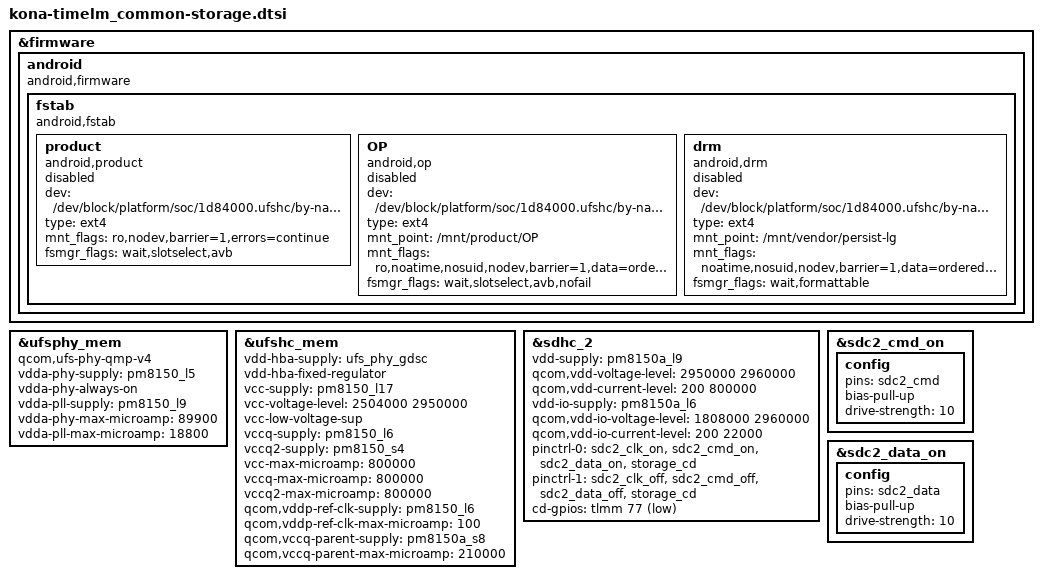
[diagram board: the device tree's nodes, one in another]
// SPDX-License-Identifier: GPL-2.0-only
/*
 * Copyright (c) 2018-2019, The Linux Foundation. All rights reserved.
 */

&firmware {
	android {
		compatible = "android,firmware";
		fstab {
			compatible = "android,fstab";
			product {
				compatible = "android,product";
				dev = "/dev/block/platform/soc/1d84000.ufshc/by-name/product";
				type = "ext4";
				mnt_flags = "ro,nodev,barrier=1,errors=continue";
				fsmgr_flags = "wait,slotselect,avb";
				status = "disabled";
			};
			OP {
				compatible = "android,op";
				dev = "/dev/block/platform/soc/1d84000.ufshc/by-name/OP";
				type = "ext4";
				mnt_point = "/mnt/product/OP";
				mnt_flags = "ro,noatime,nosuid,nodev,barrier=1,data=ordered,noauto_da_alloc";
				fsmgr_flags = "wait,slotselect,avb,nofail";
				status = "disabled";
			};
			drm {
				compatible = "android,drm";
				dev = "/dev/block/platform/soc/1d84000.ufshc/by-name/drm";
				type = "ext4";
				mnt_point = "/mnt/vendor/persist-lg";
				mnt_flags = "noatime,nosuid,nodev,barrier=1,data=ordered,noauto_da_alloc,errors=continue";
				fsmgr_flags = "wait,formattable";
				status = "disabled";
			};
		};
	};
};

&ufsphy_mem {
    compatible = "qcom,ufs-phy-qmp-v4";

    vdda-phy-supply = <&pm8150_l5>;
    vdda-phy-always-on;
    vdda-pll-supply = <&pm8150_l9>;
    vdda-phy-max-microamp = <89900>;
    vdda-pll-max-microamp = <18800>;

    status = "ok";
};

&ufshc_mem {
    vdd-hba-supply = <&ufs_phy_gdsc>;
    vdd-hba-fixed-regulator;
    vcc-supply = <&pm8150_l17>;
    vcc-voltage-level = <2504000 2950000>;
    vcc-low-voltage-sup;
    vccq-supply = <&pm8150_l6>;
    vccq2-supply = <&pm8150_s4>;
    vcc-max-microamp = <800000>;
    vccq-max-microamp = <800000>;
    vccq2-max-microamp = <800000>;

    qcom,vddp-ref-clk-supply = <&pm8150_l6>;
    qcom,vddp-ref-clk-max-microamp = <100>;
    qcom,vccq-parent-supply = <&pm8150a_s8>;
    qcom,vccq-parent-max-microamp = <210000>;

    status = "ok";
};

&sdhc_2 {
    vdd-supply = <&pm8150a_l9>;
    qcom,vdd-voltage-level = <2950000 2960000>;
    qcom,vdd-current-level = <200 800000>;

    vdd-io-supply = <&pm8150a_l6>;
    qcom,vdd-io-voltage-level = <1808000 2960000>;
    qcom,vdd-io-current-level = <200 22000>;

    pinctrl-names = "active", "sleep";
    pinctrl-0 = <&sdc2_clk_on  &sdc2_cmd_on &sdc2_data_on &storage_cd>;
    pinctrl-1 = <&sdc2_clk_off &sdc2_cmd_off &sdc2_data_off &storage_cd>;

    cd-gpios = <&tlmm 77 GPIO_ACTIVE_LOW>;

    status = "ok";
};

/* override default 16/16/16 to 16/10/10 to remove overshoot at 3.0v swing */
&sdc2_cmd_on {
    config {
		pins = "sdc2_cmd";
		bias-pull-up;
		drive-strength = <10>;
	};
};

&sdc2_data_on {
	config {
		pins = "sdc2_data";
		bias-pull-up;
		drive-strength = <10>;
	};
};
